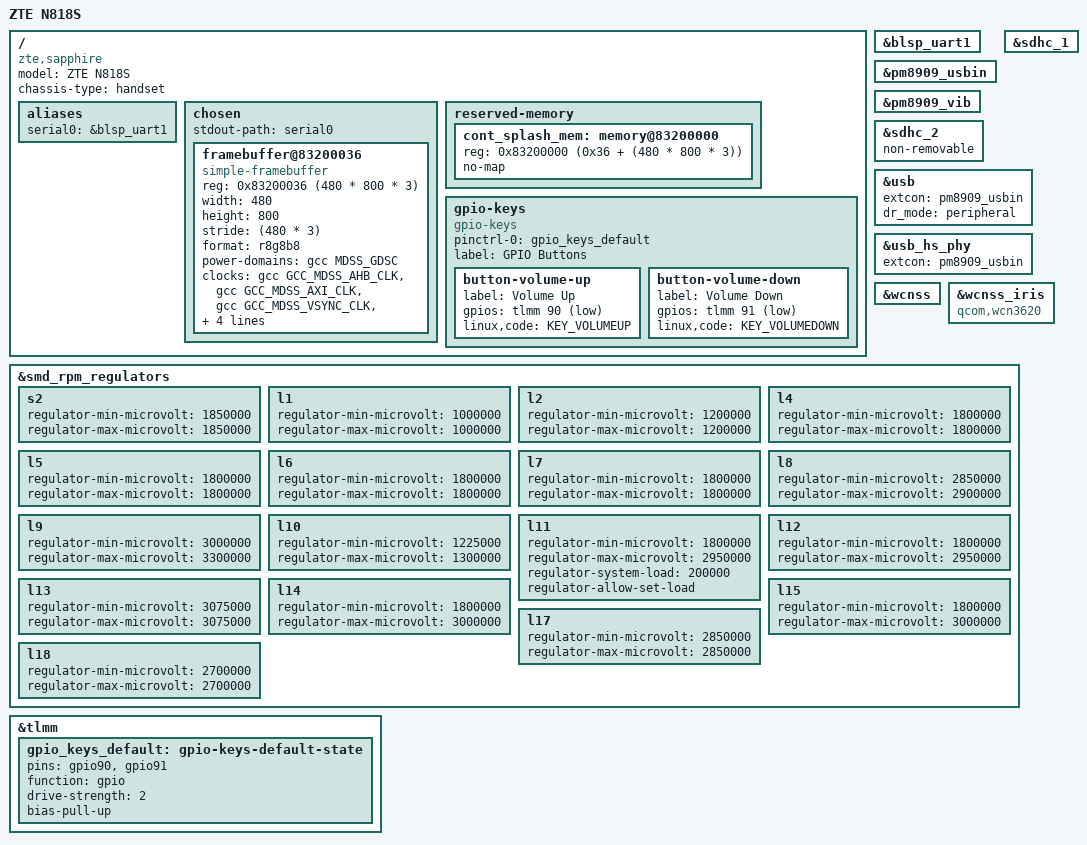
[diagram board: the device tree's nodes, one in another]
// SPDX-License-Identifier: GPL-2.0-only

/dts-v1/;

#include "qcom-msm8909-pm8909.dtsi"

#include <dt-bindings/gpio/gpio.h>
#include <dt-bindings/input/input.h>
#include <dt-bindings/interrupt-controller/irq.h>

/ {
	model = "ZTE N818S";
	compatible = "zte,sapphire", "qcom,msm8909";
	chassis-type = "handset";

	aliases {
		serial0 = &blsp_uart1;
	};

	chosen {
		#address-cells = <1>;
		#size-cells = <1>;
		ranges;
		stdout-path = "serial0";

		framebuffer@83200036 {
			compatible = "simple-framebuffer";

			/*
			 * The downstream bootloader gives us this unaligned framebuffer.
			 * We should also have a memory-region here, however memory-regions
			 * must be page-aligned, and with 0x83200000 the image is distorted
			 */

			reg = <0x83200036 (480 * 800 * 3)>;
			width = <480>;
			height = <800>;
			stride = <(480 * 3)>;
			format = "r8g8b8";

			power-domains = <&gcc MDSS_GDSC>;

			clocks = <&gcc GCC_MDSS_AHB_CLK>,
				 <&gcc GCC_MDSS_AXI_CLK>,
				 <&gcc GCC_MDSS_VSYNC_CLK>,
				 <&gcc GCC_MDSS_MDP_CLK>,
				 <&gcc GCC_MDSS_BYTE0_CLK>,
				 <&gcc GCC_MDSS_PCLK0_CLK>,
				 <&gcc GCC_MDSS_ESC0_CLK>;
		};
	};

	reserved-memory {
		/*
		 * The reserved memory for the framebuffer should start at 0x83200036
		 * However this causes a crash, as memory reserves must align to page boundaries.
		 * Therefore we must align it and add the extra 0x36 to the size.
		 */

		cont_splash_mem: memory@83200000 {
			reg = <0x83200000 (0x36 + (480 * 800 * 3))>;
			no-map;
		};
	};

	gpio-keys {
		compatible = "gpio-keys";

		pinctrl-0 = <&gpio_keys_default>;
		pinctrl-names = "default";

		label = "GPIO Buttons";

		button-volume-up {
			label = "Volume Up";
			gpios = <&tlmm 90 GPIO_ACTIVE_LOW>;
			linux,code = <KEY_VOLUMEUP>;
		};

		button-volume-down {
			label = "Volume Down";
			gpios = <&tlmm 91 GPIO_ACTIVE_LOW>;
			linux,code = <KEY_VOLUMEDOWN>;
		};
	};
};

&blsp_uart1 {
	status = "okay";
};

&pm8909_usbin {
	status = "okay";
};

&pm8909_vib {
	status = "okay";
};

&sdhc_1 {
	status = "okay";
};

&sdhc_2 {
	non-removable;
	status = "okay";
};

&usb {
	extcon = <&pm8909_usbin>;
	dr_mode = "peripheral";
	status = "okay";
};

&usb_hs_phy {
	extcon = <&pm8909_usbin>;
};

&wcnss {
	status = "okay";
};

&wcnss_iris {
	compatible = "qcom,wcn3620";
};

&smd_rpm_regulators {
	s2 {
		regulator-min-microvolt = <1850000>;
		regulator-max-microvolt = <1850000>;
	};

	l1 {
		regulator-min-microvolt = <1000000>;
		regulator-max-microvolt = <1000000>;
	};

	l2 {
		regulator-min-microvolt = <1200000>;
		regulator-max-microvolt = <1200000>;
	};

	l4 {
		regulator-min-microvolt = <1800000>;
		regulator-max-microvolt = <1800000>;
	};

	l5 {
		regulator-min-microvolt = <1800000>;
		regulator-max-microvolt = <1800000>;
	};

	l6 {
		regulator-min-microvolt = <1800000>;
		regulator-max-microvolt = <1800000>;
	};

	l7 {
		regulator-min-microvolt = <1800000>;
		regulator-max-microvolt = <1800000>;
	};

	l8 {
		regulator-min-microvolt = <2850000>;
		regulator-max-microvolt = <2900000>;
	};

	l9 {
		regulator-min-microvolt = <3000000>;
		regulator-max-microvolt = <3300000>;
	};

	l10 {
		regulator-min-microvolt = <1225000>;
		regulator-max-microvolt = <1300000>;
	};

	l11 {
		regulator-min-microvolt = <1800000>;
		regulator-max-microvolt = <2950000>;
		regulator-system-load = <200000>;
		regulator-allow-set-load;
	};

	l12 {
		regulator-min-microvolt = <1800000>;
		regulator-max-microvolt = <2950000>;
	};

	l13 {
		regulator-min-microvolt = <3075000>;
		regulator-max-microvolt = <3075000>;
	};

	l14 {
		regulator-min-microvolt = <1800000>;
		regulator-max-microvolt = <3000000>;
	};

	l15 {
		regulator-min-microvolt = <1800000>;
		regulator-max-microvolt = <3000000>;
	};

	l17 {
		regulator-min-microvolt = <2850000>;
		regulator-max-microvolt = <2850000>;
	};

	l18 {
		regulator-min-microvolt = <2700000>;
		regulator-max-microvolt = <2700000>;
	};
};

&tlmm {
	gpio_keys_default: gpio-keys-default-state {
		pins = "gpio90", "gpio91";
		function = "gpio";
		drive-strength = <2>;
		bias-pull-up;
	};
};
